# PIC16F570 register map
Vendor: Microchip
Architecture 16c5x. Special function registers and configuration words.
Registers are 8-bit, read-write, no defined reset value unless marked. A register's access mark holds for its fields unless they carry their own. Addresses are absolute, and some are shared; only a register's first bit layout is shown; lines under a group give offsets from that group; [hi:lo] are bit positions; {n}, {i} and the like mark numbered series; 'fields as' and 'values as' point back to an identical list; <NAME> marks a mode.

## Further device data
pins=1: VPP/MCLR; 2: RA0/AN0; 3: RA1/AN1/C1IN+; 4: RA2/AN2/CVREF1; 5: RA3/AN3/C2IN+; 6: RA4/AN4/T0CKI; 7: RA5/AN5; 8: VSS; 9: RA7/CLKIN/OSC1; 10: RA6/CLKOUT/OSC2; 11: RC0; 12: RC1/AN6/OPA1OUT; 13: RC2/OPA1IN-; 14: RC3/OPA1IN+; 15: RC4/OPA2IN+; 16: RC5/OPA2IN-; 17: RC6/AN7/OPA2OUT; 18: RC7/C2IN-; 19: VSS; 20: VDD; 21: RB0; 22: RB1; 23: RB2; 24: RB3/C1OUT; 25: RB4/C2OUT; 26: RB5; 27: RB6/ICSPCLK; 28: RB7/ICSPDAT/C1IN-/CVREF2

## SFR
0x00 INDF access not given
0x01 TMR0 — (power-on value xxxxxxxx)
0x02 PCL reset 0xFF
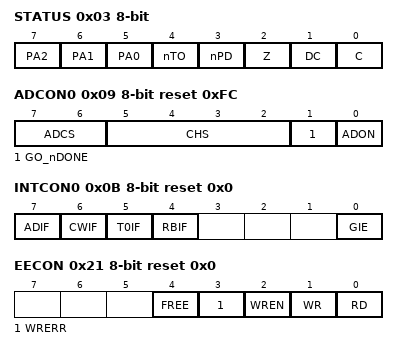
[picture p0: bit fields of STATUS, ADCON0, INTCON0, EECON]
0x03 STATUS — (power-on value x0011xxx)
  [7] PA2, [6] PA1, [5] PA0, [4] nTO, [3] nPD, [2] Z, [1] DC, [0] C
0x04 FSR — (power-on value xxxxxxxx)
0x05 OSCCAL reset 0xFE
  [7:1] CAL
0x06 PORTA — (power-on value xxxxxxxx)
  [7:0] RA
0x07 PORTB — (power-on value xxxxxxxx)
  [7:0] RB
0x08 PORTC — (power-on value xxxxxxxx)
  [7:0] RC
0x09 ADCON0 reset 0xFC
  [7:6] ADCS, [5:2] CHS, [1] GO_nDONE, [0] ADON
0x0A ADRES — (power-on value xxxxxxxx)
0x0B INTCON0 reset 0x0
  [7] ADIF, [6] CWIF, [5] T0IF, [4] RBIF, [0] GIE
0x21 EECON reset 0x0
  [4] FREE
  [3] WRERR
  [2] WREN
  [1] WR — (can only be set)
  [0] RD — (can only be set)
0x25 EEDATA — (power-on value xxxxxxxx)
0x26 EEADR — (power-on value --xxxxxx)
  [5:0] EEADR
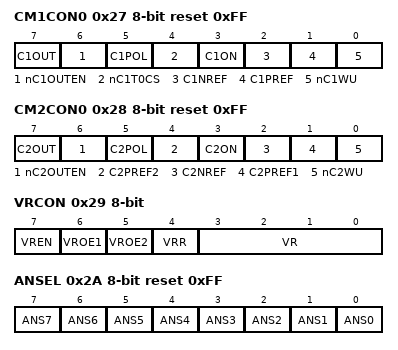
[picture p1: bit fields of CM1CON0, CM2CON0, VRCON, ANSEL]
0x27 CM1CON0 reset 0xFF
  [7] C1OUT ro, [6] nC1OUTEN, [5] C1POL, [4] nC1T0CS, [3] C1ON, [2] C1NREF, [1] C1PREF, [0] nC1WU
0x28 CM2CON0 reset 0xFF
  [7] C2OUT ro, [6] nC2OUTEN, [5] C2POL, [4] C2PREF2, [3] C2ON, [2] C2NREF, [1] C2PREF1, [0] nC2WU
0x29 VRCON — (power-on value 001x1111)
  [7] VREN, [6] VROE1, [5] VROE2, [4] VRR, [3:0] VR
0x2A ANSEL reset 0xFF
  [n] ANS{n} (n=0..7)
0x61 IW — (power-on value qqqqqqqq)
  [7:0] IWREG
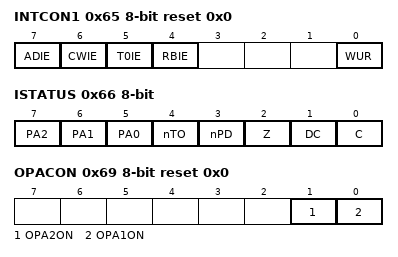
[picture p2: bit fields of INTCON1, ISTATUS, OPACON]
0x65 INTCON1 reset 0x0
  [7] ADIE, [6] CWIE, [5] T0IE, [4] RBIE, [0] WUR
0x66 ISTATUS — (power-on value x0011xxx)
  [7] PA2, [6] PA1, [5] PA0, [4] nTO, [3] nPD, [2] Z, [1] DC, [0] C
0x67 IFSR — (power-on value xxxxxxxx)
0x68 IBSR — (power-on value -----xxx)
  [2:0] IBSR
0x69 OPACON reset 0x0
  [1] OPA2ON, [0] OPA1ON

## CONFIG — Configuration words, addresses in ProgramSpace
0xFFF CONFIG 10-bit reset 0x3FF
  [9] DRTEN
    1=ON (DRT Enabled); 0=OFF (DRT Disabled)
  [8] BOREN
    1=ON (BOR Enabled); 0=OFF (BOR Disabled)
  [7] CPSW — Code Protection bit - Flash Data Memory
    1=OFF (Code protection off); 0=ON (Code protection on)
  [6] IOSCFS — Internal Oscillator Frequency Select
    1=8 MHz INTOSC Speed; 0=4 MHz INTOSC Speed
  [4] CP — Code Protection bit
    1=OFF (Code protection off); 0=ON (Code protection on)
  [3] WDTE — Watchdog Timer Enable bit
    1=ON (Enabled); 0=OFF (Disabled)
  [2:0] FOSC — Oscillator
    0=LP (LP oscillator and 18 ms DRT); 1=XT (XT oscillator and 18 ms DRT); 2=HS (HS oscillator and 18 ms DRT); 3=EC (EC oscillator with I/O function on OSC2/CLKOUT); 4=INTRC_IO (INTRC with I/O function on OSC2/CLKOUT); 5=INTRC_CLKOUT (INTRC with CLKOUT function on OSC2/CLKOUT); 6=EXTRC_IO (EXTRC with I/O function on OSC2/CLKOUT); 7=EXTRC_CLKOUT (EXTRC with CLKOUT function on OSC2/CLKOUT)
